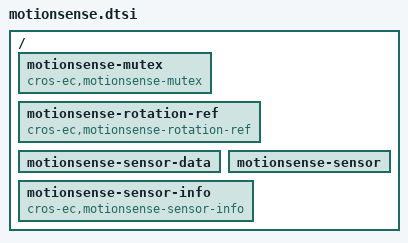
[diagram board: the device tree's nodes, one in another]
/* Copyright 2025 The ChromiumOS Authors
 * Use of this source code is governed by a BSD-style license that can be
 * found in the LICENSE file.
 */

/ {
	motionsense-mutex {
		compatible = "cros-ec,motionsense-mutex";
	};
	motionsense-rotation-ref {
		compatible = "cros-ec,motionsense-rotation-ref";
	};
	motionsense-sensor-data {};
	motionsense-sensor {};
	motionsense-sensor-info {
		compatible = "cros-ec,motionsense-sensor-info";
	};
};
